VERSION ""

NS_ :

BS_:

BU_: Gateway DOOR_ri DOOR_le Dashboard Console

BO_ 3221225472 VECTOR__INDEPENDENT_SIG_MSG: 0 Vector__XXX
 SG_ CarSpeed : 0|16@1+ (0.5,0) [0|300] "mph" Vector__XXX

BO_ 1638 bbbb: 1 DOOR_le
 SG_ aaa : 0|8@1- (1,0) [0|0] "" Vector__XXX

BO_ 1911 test2: 1 DOOR_le
 SG_ test : 0|8@1- (1,0) [0|200] "" Vector__XXX

BO_ 1541 TP_Dashboard: 6 Dashboard
 SG_ data : 0|48@1+ (1,0) [0|0] ""  Console

BO_ 1793 Diag_Request: 8 Vector__XXX

BO_ 1558 Diag_Response: 8 Vector__XXX

BO_ 1537 DiagResponse_Motor: 8 Gateway

BO_ 1543 DiagResponse_DoorLeft: 2 DOOR_le
 SG_ Data1 : 0|16@1- (1,0) [0|0] "" Vector__XXX

BO_ 1542 DiagRequest: 8 Vector__XXX

BO_ 1540 TP_Console: 6 Console

BO_ 1053 NM_Gateway: 4 Gateway
 SG_ SleepInd : 12|1@1+ (1,0) [0|0] ""  Gateway,DOOR_ri,DOOR_le

BO_ 1052 NM_DOORright: 1 DOOR_ri
 SG_ WN_Position : 0|8@1+ (1,0) [0|100] ""  DOOR_ri

BO_ 1051 NM_DOORleft: 2 Vector__XXX
 SG_ Data1 : 0|16@1- (1,0) [0|0] "" Vector__XXX

BO_ 1050 NM_Console: 2 Console
 SG_ CarSpeed : 0|16@1+ (0.5,0) [0|300] "mph" Vector__XXX

BO_ 497 DOOR_r: 1 DOOR_ri
 SG_ WN_Position : 0|8@1+ (1,0) [0|100] "" Vector__XXX

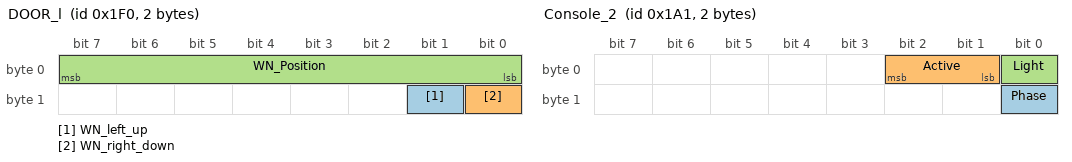
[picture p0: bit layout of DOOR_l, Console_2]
BO_ 496 DOOR_l: 2 DOOR_le
 SG_ WN_left_up : 9|1@1+ (1,0) [0|0] "" Vector__XXX
 SG_ WN_right_down : 8|1@1+ (1,0) [0|0] "" Vector__XXX
 SG_ WN_Position : 0|8@1+ (1,0) [0|100] "" Vector__XXX

BO_ 417 Console_2: 2 Console
 SG_ Phase : 8|1@1+ (1,0) [0|0] "" Vector__XXX
 SG_ Active : 1|2@1+ (1,0) [0|0] "" Vector__XXX
 SG_ Light : 0|1@1+ (1,0) [0|1] "" Vector__XXX

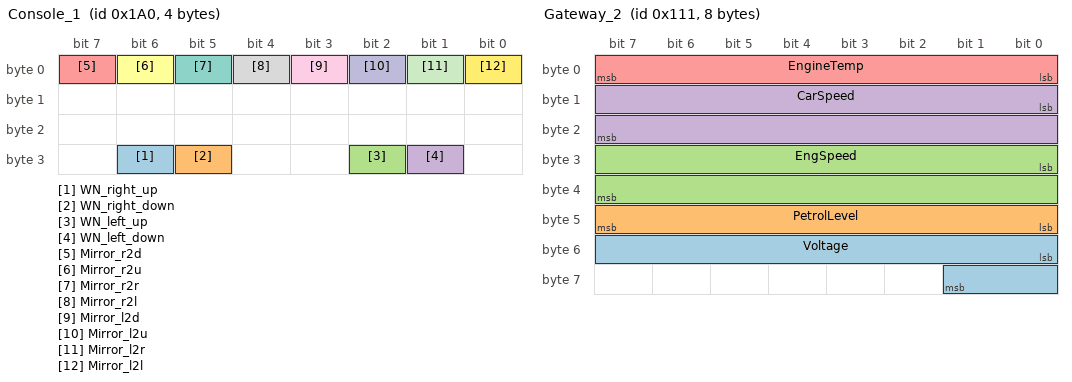
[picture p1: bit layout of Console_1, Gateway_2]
BO_ 416 Console_1: 4 Console
 SG_ WN_right_up : 30|1@1+ (1,0) [0|0] ""  DOOR_ri
 SG_ WN_right_down : 29|1@1+ (1,0) [0|0] ""  DOOR_ri
 SG_ WN_left_up : 26|1@1+ (1,0) [0|0] ""  DOOR_le
 SG_ WN_left_down : 25|1@1+ (1,0) [0|0] ""  DOOR_le
 SG_ Mirror_r2d : 7|1@1+ (1,0) [0|0] "" Vector__XXX
 SG_ Mirror_r2u : 6|1@1+ (1,0) [0|0] "" Vector__XXX
 SG_ Mirror_r2r : 5|1@1+ (1,0) [0|0] "" Vector__XXX
 SG_ Mirror_r2l : 4|1@1+ (1,0) [0|0] "" Vector__XXX
 SG_ Mirror_l2d : 3|1@1+ (1,0) [0|0] "" Vector__XXX
 SG_ Mirror_l2u : 2|1@1+ (1,0) [0|0] "" Vector__XXX
 SG_ Mirror_l2r : 1|1@1+ (1,0) [0|0] "" Vector__XXX
 SG_ Mirror_l2l : 0|1@1+ (1,0) [0|0] "" Vector__XXX

BO_ 273 Gateway_2: 8 DOOR_le
 SG_ Voltage : 48|10@1+ (0.1,0) [0|102.3] "V" Vector__XXX
 SG_ PetrolLevel : 40|8@1+ (1,0) [0|0] "l"  Dashboard
 SG_ EngSpeed : 24|16@1+ (1,0) [0|0] "rpm"  Dashboard
 SG_ CarSpeed : 8|16@1+ (0.5,0) [0|300] "mph"  Dashboard
 SG_ EngineTemp : 0|8@1+ (1,0) [0|0] "degC"  Dashboard

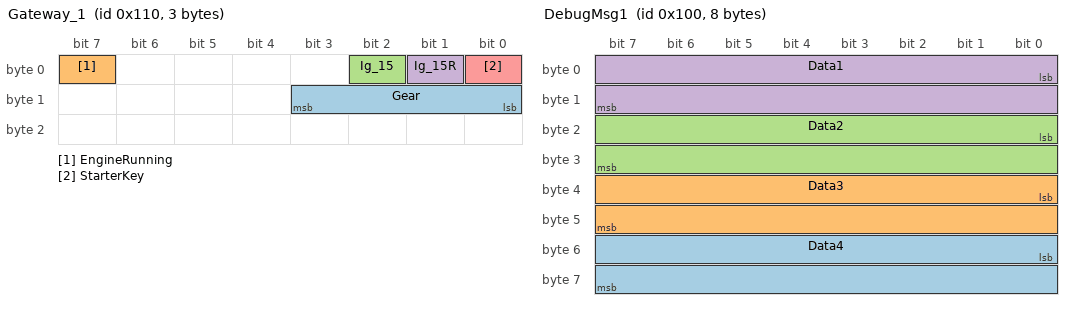
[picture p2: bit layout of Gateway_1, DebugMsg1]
BO_ 272 Gateway_1: 3 Gateway
 SG_ Gear : 8|4@1- (1,0) [0|0] ""  Dashboard
 SG_ EngineRunning : 7|1@1+ (1,0) [0|0] "" Vector__XXX
 SG_ Ig_15 : 2|1@1+ (1,0) [0|0] ""  Dashboard,Console
 SG_ Ig_15R : 1|1@1+ (1,0) [0|0] ""  Dashboard
 SG_ StarterKey : 0|1@1+ (1,0) [0|1] ""  Dashboard

BO_ 256 DebugMsg1: 8 Vector__XXX
 SG_ Data4 : 48|16@1- (1,0) [0|0] ""  Gateway
 SG_ Data3 : 32|16@1- (1,0) [0|0] ""  Gateway
 SG_ Data2 : 16|16@1- (1,0) [0|0] ""  Gateway
 SG_ Data1 : 0|16@1- (1,0) [0|0] ""  Gateway

BO_TX_BU_ 1053 : DOOR_le,Gateway;
BO_TX_BU_ 1052 : DOOR_le,DOOR_ri;

CM_ BO_ 3221225472 "This is a message for not used signals, created by Vector CANdb++ DBC OLE DB Provider.";
BA_DEF_ BO_  "GenMsgILSupport" ENUM  "No","Yes";
BA_DEF_ BU_  "NodeLayerModules" STRING ;
BA_DEF_  "NmBaseAddress" HEX 1024 1087;
BA_DEF_ SG_  "GenSigSendType" ENUM  "Cyclic","OnWrite","OnWriteWithRepetition","OnChange","OnChangeWithRepetition","IfActive","IfActiveWithRepetition","NoSigSendType";
BA_DEF_ BO_  "GenMsgCycleTime" INT 0 0;
BA_DEF_ BO_  "GenMsgSendType" ENUM  "Cyclic","not_used","not_used","not_used","not_used","Cyclic","not_used","IfActive","NoMsgSendType";
BA_DEF_  "DBName" STRING ;
BA_DEF_  "BusType" STRING ;
BA_DEF_DEF_  "GenMsgILSupport" "Yes";
BA_DEF_DEF_  "NodeLayerModules" "CANoeILNLVector.dll";
BA_DEF_DEF_  "NmBaseAddress" 1024;
BA_DEF_DEF_  "GenSigSendType" "Cyclic";
BA_DEF_DEF_  "GenMsgCycleTime" 0;
BA_DEF_DEF_  "GenMsgSendType" "NoMsgSendType";
BA_DEF_DEF_  "DBName" "";
BA_DEF_DEF_  "BusType" "CAN";
BA_ "DBName" "CANComfort";
BA_ "GenMsgSendType" BO_ 1638 0;
BA_ "GenMsgCycleTime" BO_ 1638 100;
BA_ "GenMsgCycleTime" BO_ 1911 100;
BA_ "GenMsgSendType" BO_ 1911 0;
BA_ "GenMsgSendType" BO_ 1541 1;
BA_ "GenMsgSendType" BO_ 1793 1;
BA_ "GenMsgSendType" BO_ 1558 1;
BA_ "GenMsgSendType" BO_ 1537 1;
BA_ "GenMsgSendType" BO_ 1543 1;
BA_ "GenMsgSendType" BO_ 1542 1;
BA_ "GenMsgSendType" BO_ 1540 1;
BA_ "GenMsgSendType" BO_ 1053 1;
BA_ "GenMsgSendType" BO_ 1052 1;
BA_ "GenMsgCycleTime" BO_ 1052 500;
BA_ "GenMsgSendType" BO_ 1051 1;
BA_ "GenMsgSendType" BO_ 1050 1;
BA_ "GenMsgCycleTime" BO_ 497 100;
BA_ "GenMsgCycleTime" BO_ 496 100;
BA_ "GenMsgCycleTime" BO_ 417 50;
BA_ "GenMsgCycleTime" BO_ 416 50;
BA_ "GenMsgCycleTime" BO_ 273 100;
BA_ "GenMsgCycleTime" BO_ 272 20;
BA_ "GenMsgSendType" BO_ 256 1;
BA_ "GenSigSendType" SG_ 1541 data 7;
BA_ "GenSigSendType" SG_ 1053 SleepInd 7;
VAL_ 417 Active 0 "None" 1 "Turn_right" 2 "Turn_left" 3 "Warning" ;
VAL_ 272 Gear 5 "Gear_5" 4 "Gear_4" 3 "Gear_3" 2 "Gear_2" 1 "Gear_1" 0 "Idle" ;
